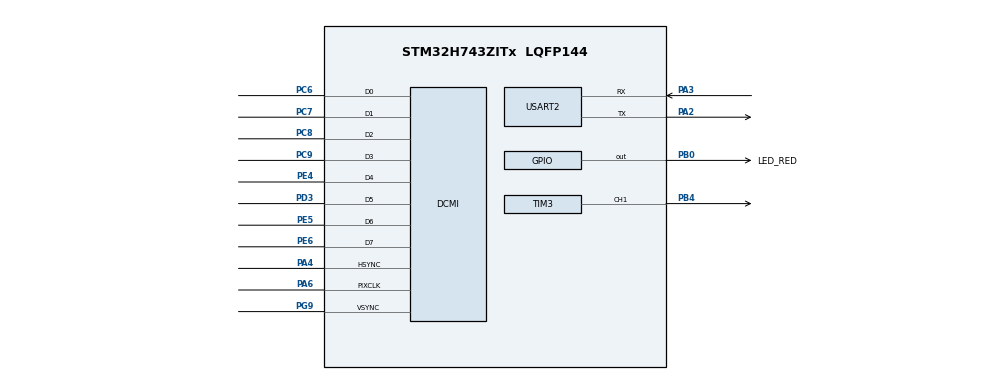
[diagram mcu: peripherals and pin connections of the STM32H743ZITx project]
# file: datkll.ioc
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Dma.DCMI.0.Direction=DMA_PERIPH_TO_MEMORY
Dma.DCMI.0.EventEnable=DISABLE
Dma.DCMI.0.FIFOMode=DMA_FIFOMODE_DISABLE
Dma.DCMI.0.Instance=DMA1_Stream0
Dma.DCMI.0.MemDataAlignment=DMA_MDATAALIGN_WORD
Dma.DCMI.0.MemInc=DMA_MINC_ENABLE
Dma.DCMI.0.Mode=DMA_CIRCULAR
Dma.DCMI.0.PeriphDataAlignment=DMA_PDATAALIGN_WORD
Dma.DCMI.0.PeriphInc=DMA_PINC_DISABLE
Dma.DCMI.0.Polarity=HAL_DMAMUX_REQ_GEN_RISING
Dma.DCMI.0.Priority=DMA_PRIORITY_LOW
Dma.DCMI.0.RequestNumber=1
Dma.DCMI.0.SignalID=NONE
Dma.DCMI.0.SyncEnable=ENABLE
Dma.DCMI.0.SyncPolarity=HAL_DMAMUX_SYNC_RISING
Dma.DCMI.0.SyncRequestNumber=1
Dma.DCMI.0.SyncSignalID=NONE
Dma.Request0=DCMI
Mcu.Family=STM32H7
Mcu.Name=STM32H743ZITx
Mcu.Package=LQFP144
NVIC.DMA1_Stream0_IRQn=true\:0\:0\:false\:false\:true\:false\:true
NVIC.DMAMUX1_OVR_IRQn=true\:0\:0\:false\:false\:true\:false\:true
NVIC.PriorityGroup=NVIC_PRIORITYGROUP_4
NVIC.TIM2_IRQn=true\:0\:0\:false\:false\:true\:true\:true
NVIC.USART2_IRQn=true\:0\:0\:false\:false\:true\:true\:true
PA13\ (JTMS/SWDIO).Mode=Serial_Wire
PA13\ (JTMS/SWDIO).Signal=DEBUG_JTMS-SWDIO
PA14\ (JTCK/SWCLK).Mode=Serial_Wire
PA14\ (JTCK/SWCLK).Signal=DEBUG_JTCK-SWCLK
PA2.Mode=Asynchronous
PA2.Signal=USART2_TX
PA3.Mode=Asynchronous
PA3.Signal=USART2_RX
PA4.Mode=Slave_8_bits_External_Synchro
PA4.Signal=DCMI_HSYNC
PA6.Mode=Slave_8_bits_External_Synchro
PA6.Signal=DCMI_PIXCLK
PB0.GPIO_Label=LED_RED
PB0.Signal=GPIO_Output
PB4\ (NJTRST).Signal=S_TIM3_CH1
PC6.Mode=Slave_8_bits_External_Synchro
PC6.Signal=DCMI_D0
PC7.Mode=Slave_8_bits_External_Synchro
PC7.Signal=DCMI_D1
PC8.Mode=Slave_8_bits_External_Synchro
PC8.Signal=DCMI_D2
PC9.Mode=Slave_8_bits_External_Synchro
PC9.Signal=DCMI_D3
PD3.Mode=Slave_8_bits_External_Synchro
PD3.Signal=DCMI_D5
PE4.Mode=Slave_8_bits_External_Synchro
PE4.Signal=DCMI_D4
PE5.Mode=Slave_8_bits_External_Synchro
PE5.Signal=DCMI_D6
PE6.Mode=Slave_8_bits_External_Synchro
PE6.Signal=DCMI_D7
PG9.Mode=Slave_8_bits_External_Synchro
PG9.Signal=DCMI_VSYNC
ProjectManager.HeapSize=0x200
ProjectManager.StackSize=0x400
ProjectManager.TargetToolchain=STM32CubeIDE
RCC.ADCFreq_Value=129000000
RCC.APB1Freq_Value=32000000
RCC.APB2Freq_Value=64000000
RCC.APB3Freq_Value=64000000
RCC.APB4Freq_Value=64000000
RCC.CortexFreq_Value=64000000
RCC.D2PPRE1=RCC_APB1_DIV2
RCC.HCLKFreq_Value=64000000
RCC.SYSCLKFreq_VALUE=64000000
RCC.USBFreq_Value=129000000
SH.S_TIM3_CH1.0=TIM3_CH1,PWM Generation1 CH1
TIM2.Period=63
TIM2.Prescaler=999
TIM3.Channel-PWM\ Generation1\ CH1=TIM_CHANNEL_1
TIM3.Period=999
TIM3.Prescaler=63
USART2.VirtualMode-Asynchronous=VM_ASYNC
USART2.WordLength=WORDLENGTH_8B
VP_TIM2_VS_ClockSourceINT.Mode=Internal
board=custom

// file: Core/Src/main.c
/* USER CODE BEGIN Header */
/**
  ******************************************************************************
  * @file           : main.c
  * @brief          : Main program body
  ******************************************************************************
  * @attention
  *
  * <h2><center>&copy; Copyright (c) 2022 STMicroelectronics.
  * All rights reserved.</center></h2>
  *
  * This software component is licensed by ST under BSD 3-Clause license,
  * the "License"; You may not use this file except in compliance with the
  * License. You may obtain a copy of the License at:
  *                        opensource.org/licenses/BSD-3-Clause
  *
  ******************************************************************************
  */
/* USER CODE END Header */
#include "main.h"

/* USER CODE BEGIN Includes */
#include "global.h"
/* USER CODE END Includes */

DCMI_HandleTypeDef hdcmi;
DMA_HandleTypeDef hdma_dcmi;

TIM_HandleTypeDef htim2;
TIM_HandleTypeDef htim3;

UART_HandleTypeDef huart2;

void SystemClock_Config(void);
static void MX_GPIO_Init(void);
static void MX_DMA_Init(void);
static void MX_DCMI_Init(void);
static void MX_TIM3_Init(void);
static void MX_USART2_UART_Init(void);
static void MX_TIM2_Init(void);

/* USER CODE BEGIN 0 */
//void HAL_UART_RxCpltCallback(UART_HandleTypeDef *huart){
//	if (huart->Instance == USART2){
//		HAL_UART_Transmit(&huart2, &temp , 1 , 50);
//		HAL_UART_Receive_IT(&huart2, &temp, 1);
//	}
//}
/* USER CODE END 0 */

int main(void)
{

  /* MCU Configuration--------------------------------------------------------*/

  /* Reset of all peripherals, Initializes the Flash interface and the Systick. */
  HAL_Init();

  /* Configure the system clock */
  SystemClock_Config();

  /* Initialize all configured peripherals */
  MX_GPIO_Init();
  MX_DMA_Init();
  MX_DCMI_Init();
  MX_TIM3_Init();
  MX_USART2_UART_Init();
  MX_TIM2_Init();
  /* USER CODE BEGIN 2 */
  HAL_TIM_Base_Start_IT(&htim2);
  HAL_UART_Receive_IT (&huart2 , &temp , 1);
  /* USER CODE END 2 */

  /* Infinite loop */
  while (1)
  {
	  //	  sendRun();
	  HAL_GPIO_WritePin(LED_RED_GPIO_Port, LED_RED_Pin, 1);
//  	  HAL_GPIO_TogglePin(LED_RED_GPIO_Port, LED_RED_Pin);
  	  HAL_Delay(100);
  }
}

void SystemClock_Config(void)
{
  RCC_OscInitTypeDef RCC_OscInitStruct = {0};
  RCC_ClkInitTypeDef RCC_ClkInitStruct = {0};

  /** Supply configuration update enable
  */
  HAL_PWREx_ConfigSupply(PWR_LDO_SUPPLY);
  /** Configure the main internal regulator output voltage
  */
  __HAL_PWR_VOLTAGESCALING_CONFIG(PWR_REGULATOR_VOLTAGE_SCALE3);

  while(!__HAL_PWR_GET_FLAG(PWR_FLAG_VOSRDY)) {}
  /** Initializes the RCC Oscillators according to the specified parameters
  * in the RCC_OscInitTypeDef structure.
  */
  RCC_OscInitStruct.OscillatorType = RCC_OSCILLATORTYPE_HSI;
  RCC_OscInitStruct.HSIState = RCC_HSI_DIV1;
  RCC_OscInitStruct.HSICalibrationValue = RCC_HSICALIBRATION_DEFAULT;
  RCC_OscInitStruct.PLL.PLLState = RCC_PLL_NONE;
  if (HAL_RCC_OscConfig(&RCC_OscInitStruct) != HAL_OK)
  {
    Error_Handler();
  }
  /** Initializes the CPU, AHB and APB buses clocks
  */
  RCC_ClkInitStruct.ClockType = RCC_CLOCKTYPE_HCLK|RCC_CLOCKTYPE_SYSCLK
                              |RCC_CLOCKTYPE_PCLK1|RCC_CLOCKTYPE_PCLK2
                              |RCC_CLOCKTYPE_D3PCLK1|RCC_CLOCKTYPE_D1PCLK1;
  RCC_ClkInitStruct.SYSCLKSource = RCC_SYSCLKSOURCE_HSI;
  RCC_ClkInitStruct.SYSCLKDivider = RCC_SYSCLK_DIV1;
  RCC_ClkInitStruct.AHBCLKDivider = RCC_HCLK_DIV1;
  RCC_ClkInitStruct.APB3CLKDivider = RCC_APB3_DIV1;
  RCC_ClkInitStruct.APB1CLKDivider = RCC_APB1_DIV2;
  RCC_ClkInitStruct.APB2CLKDivider = RCC_APB2_DIV1;
  RCC_ClkInitStruct.APB4CLKDivider = RCC_APB4_DIV1;

  if (HAL_RCC_ClockConfig(&RCC_ClkInitStruct, FLASH_LATENCY_1) != HAL_OK)
  {
    Error_Handler();
  }
}

static void MX_DCMI_Init(void)
{

  hdcmi.Instance = DCMI;
  hdcmi.Init.SynchroMode = DCMI_SYNCHRO_HARDWARE;
  hdcmi.Init.PCKPolarity = DCMI_PCKPOLARITY_FALLING;
  hdcmi.Init.VSPolarity = DCMI_VSPOLARITY_LOW;
  hdcmi.Init.HSPolarity = DCMI_HSPOLARITY_LOW;
  hdcmi.Init.CaptureRate = DCMI_CR_ALL_FRAME;
  hdcmi.Init.ExtendedDataMode = DCMI_EXTEND_DATA_8B;
  hdcmi.Init.JPEGMode = DCMI_JPEG_DISABLE;
  hdcmi.Init.ByteSelectMode = DCMI_BSM_ALL;
  hdcmi.Init.ByteSelectStart = DCMI_OEBS_ODD;
  hdcmi.Init.LineSelectMode = DCMI_LSM_ALL;
  hdcmi.Init.LineSelectStart = DCMI_OELS_ODD;
  if (HAL_DCMI_Init(&hdcmi) != HAL_OK)
  {
    Error_Handler();
  }

}

static void MX_TIM2_Init(void)
{

  TIM_ClockConfigTypeDef sClockSourceConfig = {0};
  TIM_MasterConfigTypeDef sMasterConfig = {0};

  htim2.Instance = TIM2;
  htim2.Init.Prescaler = 999;
  htim2.Init.CounterMode = TIM_COUNTERMODE_UP;
  htim2.Init.Period = 63;
  htim2.Init.ClockDivision = TIM_CLOCKDIVISION_DIV1;
  htim2.Init.AutoReloadPreload = TIM_AUTORELOAD_PRELOAD_DISABLE;
  if (HAL_TIM_Base_Init(&htim2) != HAL_OK)
  {
    Error_Handler();
  }
  sClockSourceConfig.ClockSource = TIM_CLOCKSOURCE_INTERNAL;
  if (HAL_TIM_ConfigClockSource(&htim2, &sClockSourceConfig) != HAL_OK)
  {
    Error_Handler();
  }
  sMasterConfig.MasterOutputTrigger = TIM_TRGO_RESET;
  sMasterConfig.MasterSlaveMode = TIM_MASTERSLAVEMODE_DISABLE;
  if (HAL_TIMEx_MasterConfigSynchronization(&htim2, &sMasterConfig) != HAL_OK)
  {
    Error_Handler();
  }

}

static void MX_TIM3_Init(void)
{

  TIM_MasterConfigTypeDef sMasterConfig = {0};
  TIM_OC_InitTypeDef sConfigOC = {0};

  htim3.Instance = TIM3;
  htim3.Init.Prescaler = 63;
  htim3.Init.CounterMode = TIM_COUNTERMODE_UP;
  htim3.Init.Period = 999;
  htim3.Init.ClockDivision = TIM_CLOCKDIVISION_DIV1;
  htim3.Init.AutoReloadPreload = TIM_AUTORELOAD_PRELOAD_DISABLE;
  if (HAL_TIM_PWM_Init(&htim3) != HAL_OK)
  {
    Error_Handler();
  }
  sMasterConfig.MasterOutputTrigger = TIM_TRGO_RESET;
  sMasterConfig.MasterSlaveMode = TIM_MASTERSLAVEMODE_DISABLE;
  if (HAL_TIMEx_MasterConfigSynchronization(&htim3, &sMasterConfig) != HAL_OK)
  {
    Error_Handler();
  }
  sConfigOC.OCMode = TIM_OCMODE_PWM1;
  sConfigOC.Pulse = 0;
  sConfigOC.OCPolarity = TIM_OCPOLARITY_HIGH;
  sConfigOC.OCFastMode = TIM_OCFAST_DISABLE;
  if (HAL_TIM_PWM_ConfigChannel(&htim3, &sConfigOC, TIM_CHANNEL_1) != HAL_OK)
  {
    Error_Handler();
  }
  HAL_TIM_MspPostInit(&htim3);

}

static void MX_USART2_UART_Init(void)
{

  huart2.Instance = USART2;
  huart2.Init.BaudRate = 115200;
  huart2.Init.WordLength = UART_WORDLENGTH_8B;
  huart2.Init.StopBits = UART_STOPBITS_1;
  huart2.Init.Parity = UART_PARITY_NONE;
  huart2.Init.Mode = UART_MODE_TX_RX;
  huart2.Init.HwFlowCtl = UART_HWCONTROL_NONE;
  huart2.Init.OverSampling = UART_OVERSAMPLING_16;
  huart2.Init.OneBitSampling = UART_ONE_BIT_SAMPLE_DISABLE;
  huart2.Init.ClockPrescaler = UART_PRESCALER_DIV1;
  huart2.AdvancedInit.AdvFeatureInit = UART_ADVFEATURE_NO_INIT;
  if (HAL_UART_Init(&huart2) != HAL_OK)
  {
    Error_Handler();
  }
  if (HAL_UARTEx_SetTxFifoThreshold(&huart2, UART_TXFIFO_THRESHOLD_1_8) != HAL_OK)
  {
    Error_Handler();
  }
  if (HAL_UARTEx_SetRxFifoThreshold(&huart2, UART_RXFIFO_THRESHOLD_1_8) != HAL_OK)
  {
    Error_Handler();
  }
  if (HAL_UARTEx_DisableFifoMode(&huart2) != HAL_OK)
  {
    Error_Handler();
  }

}

static void MX_DMA_Init(void)
{

  /* DMA controller clock enable */
  __HAL_RCC_DMA1_CLK_ENABLE();

  /* DMA interrupt init */
  /* DMA1_Stream0_IRQn interrupt configuration */
  HAL_NVIC_SetPriority(DMA1_Stream0_IRQn, 0, 0);
  HAL_NVIC_EnableIRQ(DMA1_Stream0_IRQn);
  /* DMAMUX1_OVR_IRQn interrupt configuration */
  HAL_NVIC_SetPriority(DMAMUX1_OVR_IRQn, 0, 0);
  HAL_NVIC_EnableIRQ(DMAMUX1_OVR_IRQn);

}

static void MX_GPIO_Init(void)
{
  GPIO_InitTypeDef GPIO_InitStruct = {0};

  /* GPIO Ports Clock Enable */
  __HAL_RCC_GPIOE_CLK_ENABLE();
  __HAL_RCC_GPIOA_CLK_ENABLE();
  __HAL_RCC_GPIOB_CLK_ENABLE();
  __HAL_RCC_GPIOC_CLK_ENABLE();
  __HAL_RCC_GPIOD_CLK_ENABLE();
  __HAL_RCC_GPIOG_CLK_ENABLE();

  /*Configure GPIO pin Output Level */
  HAL_GPIO_WritePin(LED_RED_GPIO_Port, LED_RED_Pin, GPIO_PIN_RESET);

  /*Configure GPIO pin : LED_RED_Pin */
  GPIO_InitStruct.Pin = LED_RED_Pin;
  GPIO_InitStruct.Mode = GPIO_MODE_OUTPUT_PP;
  GPIO_InitStruct.Pull = GPIO_NOPULL;
  GPIO_InitStruct.Speed = GPIO_SPEED_FREQ_LOW;
  HAL_GPIO_Init(LED_RED_GPIO_Port, &GPIO_InitStruct);

}

void Error_Handler(void)
{
  __disable_irq();
  while (1)
  {
  }
}

/************************ (C) COPYRIGHT STMicroelectronics *****END OF FILE****/
